# LAN9255ZMX018 register map
Vendor: Microchip
Registers are 32-bit, read-write, reset 0x0 unless marked. A register's access mark holds for its fields unless they carry their own. Addresses are absolute, and some are shared; only a register's first bit layout is shown; [hi:lo] are bit positions; {n}, {i} and the like mark numbered series; 'fields as' and 'values as' point back to an identical list.

## SUPC
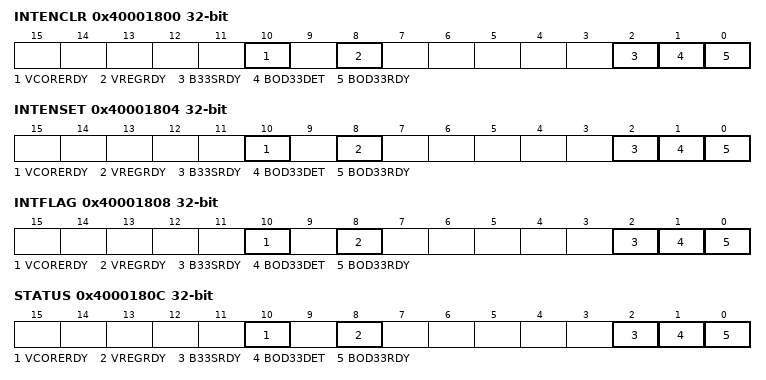
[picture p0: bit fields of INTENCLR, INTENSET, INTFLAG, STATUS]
0x40001800 INTENCLR
  [10] VCORERDY — VDDCORE Ready
  [8] VREGRDY — Voltage Regulator Ready
  [2] B33SRDY — BOD33 Synchronization Ready
  [1] BOD33DET — BOD33 Detection
  [0] BOD33RDY — BOD33 Ready
0x40001804 INTENSET
  fields as INTENCLR
0x40001808 INTFLAG
  fields as INTENCLR
0x4000180C STATUS ro
  fields as INTENCLR
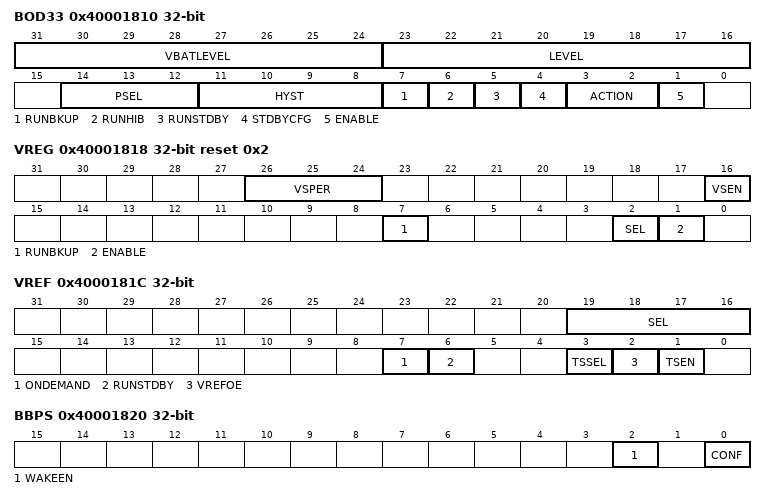
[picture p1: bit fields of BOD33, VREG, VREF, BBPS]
0x40001810 BOD33
  [31:24] VBATLEVEL — Threshold Level in battery backup sleep mode for VBAT
  [23:16] LEVEL — Threshold Level for VDD
  [14:12] PSEL — Prescaler Select
    0=NODIV (Not divided); 1=DIV4 (Divide clock by 4); 2=DIV8 (Divide clock by 8); 3=DIV16 (Divide clock by 16); 4=DIV32 (Divide clock by 32); 5=DIV64 (Divide clock by 64); 6=DIV128 (Divide clock by 128); 7=DIV256 (Divide clock by 256)
  [11:8] HYST — Hysteresis value
  [7] RUNBKUP — Run in Backup mode
  [6] RUNHIB — Run in Hibernate mode
  [5] RUNSTDBY — Run in Standby mode
  [4] STDBYCFG — Configuration in Standby mode
  [3:2] ACTION — Action when Threshold Crossed
    0=NONE (No action); 1=RESET (The BOD33 generates a reset); 2=INT (The BOD33 generates an interrupt); 3=BKUP (The BOD33 puts the device in backup sleep mode)
  [1] ENABLE
0x40001818 VREG reset 0x2
  [26:24] VSPER — Voltage Scaling Period
  [16] VSEN — Voltage Scaling Enable
  [7] RUNBKUP — Run in Backup mode
  [2] SEL — Voltage Regulator Selection
    0=LDO (LDO selection); 1=BUCK (Buck selection)
  [1] ENABLE
0x4000181C VREF
  [19:16] SEL — Voltage Reference Selection
    0=1V0 (1.0V voltage reference typical value); 1=1V1 (1.1V voltage reference typical value); 2=1V2 (1.2V voltage reference typical value); 3=1V25 (1.25V voltage reference typical value); 4=2V0 (2.0V voltage reference typical value); 5=2V2 (2.2V voltage reference typical value); 6=2V4 (2.4V voltage reference typical value); 7=2V5 (2.5V voltage reference typical value)
  [7] ONDEMAND — On Demand Contrl
  [6] RUNSTDBY — Run during Standby
  [3] TSSEL — Temperature Sensor Selection
  [2] VREFOE — Voltage Reference Output Enable
  [1] TSEN — Temperature Sensor Output Enable
0x40001820 BBPS
  [2] WAKEEN — Wake Enable
  [0] CONF — Battery Backup Configuration
    0=BOD33 (The power switch is handled by the BOD33); 1=FORCED (In Backup Domain, the backup domain is always supplied by battery backup power)
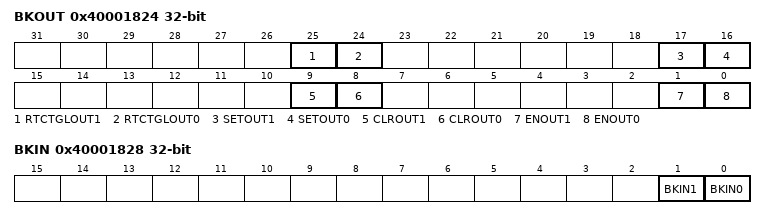
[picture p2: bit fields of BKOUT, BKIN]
0x40001824 BKOUT
  [25] RTCTGLOUT1 — RTC Toggle OUT1
  [24] RTCTGLOUT0 — RTC Toggle OUT0
  [17] SETOUT1
  [16] SETOUT0
  [9] CLROUT1 — Clear OUT1
  [8] CLROUT0 — Clear OUT0
  [1] ENOUT1 — Enable OUT1
  [0] ENOUT0 — Enable OUT0
0x40001828 BKIN ro
  [1] BKIN1 — Backup Input 1
  [0] BKIN0 — Backup Input 0

## GCLK
0x40001C00 CTRLA 8-bit
  [0] SWRST — Software Reset
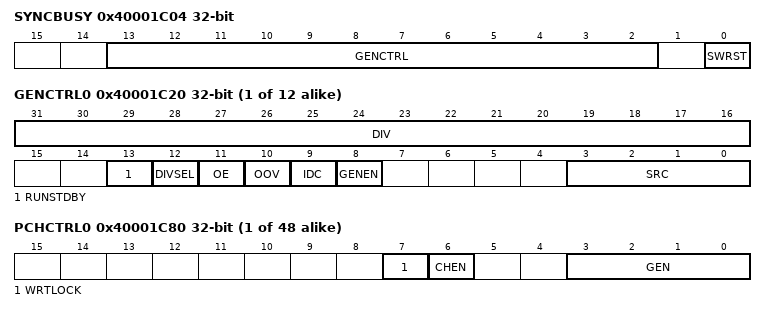
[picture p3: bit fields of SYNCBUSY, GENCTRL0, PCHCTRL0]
0x40001C04 SYNCBUSY ro
  [13:2] GENCTRL — Generic Clock Generator Control n Synchronization Busy bits
    1=GCLK0 (Generic clock generator 0); 2=GCLK1 (Generic clock generator 1); 4=GCLK2 (Generic clock generator 2); 8=GCLK3 (Generic clock generator 3); 16=GCLK4 (Generic clock generator 4); 32=GCLK5 (Generic clock generator 5); 64=GCLK6 (Generic clock generator 6); 128=GCLK7 (Generic clock generator 7); 0x100=GCLK8 (Generic clock generator 8); 0x200=GCLK9 (Generic clock generator 9); 0x400=GCLK10 (Generic clock generator 10); 0x800=GCLK11 (Generic clock generator 11)
  [0] SWRST — Software Reset Synchroniation Busy bit
{0x40001C20+4i} GENCTRL{i} (i=0..11)
  [31:16] DIV — Division Factor
  [13] RUNSTDBY — Run in Standby
  [12] DIVSEL — Divide Selection
    0=DIV1 (Divide input directly by divider factor); 1=DIV2 (Divide input by 2^(divider factor+ 1))
  [11] OE — Output Enable
  [10] OOV — Output Off Value
  [9] IDC — Improve Duty Cycle
  [8] GENEN — Generic Clock Generator Enable
  [3:0] SRC — Source Select
    0=XOSC0 (XOSC0 oscillator output); 1=XOSC1 (XOSC1 oscillator output); 2=GCLKIN (Generator input pad); 3=GCLKGEN1 (Generic clock generator 1 output); 4=OSCULP32K (OSCULP32K oscillator output); 5=XOSC32K (XOSC32K oscillator output); 6=DFLL (DFLL output); 7=DPLL0 (DPLL0 output); 8=DPLL1 (DPLL1 output)
{0x40001C80+4i} PCHCTRL{i} (i=0..47)
  [7] WRTLOCK — Write Lock
  [6] CHEN — Channel Enable
  [3:0] GEN — Generic Clock Generator
    {v}=GCLK{v} (Generic clock generator {v}) (v=0..11)
